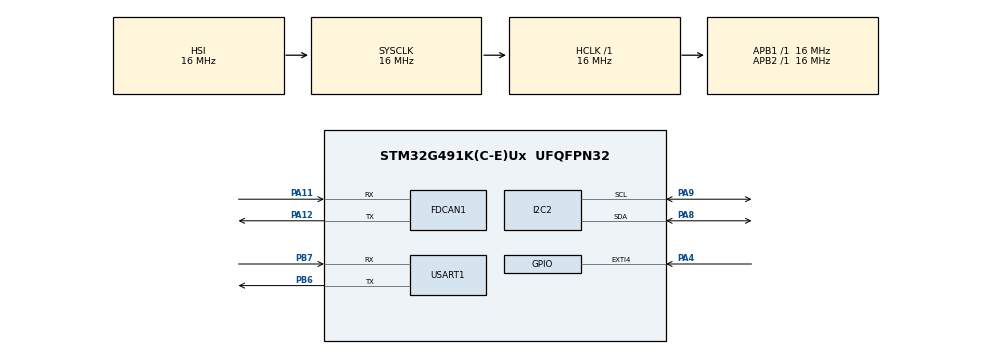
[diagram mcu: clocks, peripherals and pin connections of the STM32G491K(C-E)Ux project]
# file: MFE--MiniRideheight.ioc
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FDCAN1.CalculateBaudRateNominal=333333
FDCAN1.CalculateTimeBitNominal=3000
FDCAN1.CalculateTimeQuantumNominal=1000.0
I2C2.Timing=0x00503D58
Mcu.Family=STM32G4
Mcu.Name=STM32G491K(C-E)Ux
Mcu.Package=UFQFPN32
NVIC.EXTI4_IRQn=true\:0\:0\:false\:false\:true\:true\:true\:true
NVIC.I2C2_EV_IRQn=true\:0\:0\:false\:false\:true\:true\:true\:true
NVIC.PriorityGroup=NVIC_PRIORITYGROUP_4
PA11.Mode=FDCAN_Activate
PA11.Signal=FDCAN1_RX
PA12.Mode=FDCAN_Activate
PA12.Signal=FDCAN1_TX
PA13.Mode=Serial_Wire
PA13.Signal=SYS_JTMS-SWDIO
PA14.Mode=Serial_Wire
PA14.Signal=SYS_JTCK-SWCLK
PA4.GPIO_ModeDefaultEXTI=GPIO_MODE_IT_FALLING
PA4.Signal=GPXTI4
PA8.Mode=I2C
PA8.Signal=I2C2_SDA
PA9.Mode=I2C
PA9.Signal=I2C2_SCL
PB6.Mode=Asynchronous
PB6.Signal=USART1_TX
PB7.Mode=Asynchronous
PB7.Signal=USART1_RX
ProjectManager.HeapSize=0x200
ProjectManager.StackSize=0x400
ProjectManager.TargetToolchain=STM32CubeIDE
RCC.AHBFreq_Value=16000000
RCC.APB1Freq_Value=16000000
RCC.APB1TimFreq_Value=16000000
RCC.APB2Freq_Value=16000000
RCC.APB2TimFreq_Value=16000000
RCC.CortexFreq_Value=16000000
RCC.EXTERNAL_CLOCK_VALUE=12288000
RCC.HCLKFreq_Value=16000000
RCC.HSE_VALUE=8000000
RCC.HSI48_VALUE=48000000
RCC.HSI_VALUE=16000000
RCC.LSE_VALUE=32768
RCC.SYSCLKFreq_VALUE=16000000
RCC.VCOOutputFreq_Value=128000000
USART1.VirtualMode-Asynchronous=VM_ASYNC
VP_SYS_VS_DBSignals.Mode=DisableDeadBatterySignals
board=custom

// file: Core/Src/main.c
/* USER CODE BEGIN Header */
/**
  ******************************************************************************
  * @file           : main.c
  * @brief          : Main program body
  ******************************************************************************
  * @attention
  *
  * Copyright (c) 2026 STMicroelectronics.
  * All rights reserved.
  *
  * This software is licensed under terms that can be found in the LICENSE file
  * in the root directory of this software component.
  * If no LICENSE file comes with this software, it is provided AS-IS.
  *
  ******************************************************************************
  */
/* USER CODE END Header */
#include "main.h"
#include "fdcan.h"
#include "i2c.h"
#include "usart.h"
#include "gpio.h"

/* USER CODE BEGIN Includes */
#include "BoardManager.h"

/* USER CODE END Includes */

/* USER CODE BEGIN PD */
bool data_ready;
void* can_handle;
VL53L4CD_ResultsData_t data;

/* USER CODE END PD */

void SystemClock_Config(void);

int main(void)
{

  /* MCU Configuration--------------------------------------------------------*/

  /* Reset of all peripherals, Initializes the Flash interface and the Systick. */
  HAL_Init();

  /* Configure the system clock */
  SystemClock_Config();

  /* Initialize all configured peripherals */
  MX_GPIO_Init();
  MX_FDCAN1_Init();
  MX_I2C2_Init();
  MX_USART1_UART_Init();
  /* USER CODE BEGIN 2 */
  while (!initializeCAN()){ ; //init fdcan peripheral, keep trying until it works
  	  printf("Fdcan init failed\r\n");
  	  HAL_Delay(20);
  }

  while (!sensor_start()){
	  printf("Sensor not started"); //start the sensor
	  HAL_Delay(20);
  }
  printf("Sensor started\r\n");
  /* USER CODE END 2 */

  /* Infinite loop */
  /* USER CODE BEGIN WHILE */
  while (1)
  {
	  if (data_ready){
		  data_ready = 0;
		  get_data_it();
	  }
    /* USER CODE END WHILE */
  }
}

void SystemClock_Config(void)
{
  RCC_OscInitTypeDef RCC_OscInitStruct = {0};
  RCC_ClkInitTypeDef RCC_ClkInitStruct = {0};

  /** Configure the main internal regulator output voltage
  */
  HAL_PWREx_ControlVoltageScaling(PWR_REGULATOR_VOLTAGE_SCALE1);

  /** Initializes the RCC Oscillators according to the specified parameters
  * in the RCC_OscInitTypeDef structure.
  */
  RCC_OscInitStruct.OscillatorType = RCC_OSCILLATORTYPE_HSI;
  RCC_OscInitStruct.HSIState = RCC_HSI_ON;
  RCC_OscInitStruct.HSICalibrationValue = RCC_HSICALIBRATION_DEFAULT;
  RCC_OscInitStruct.PLL.PLLState = RCC_PLL_NONE;
  if (HAL_RCC_OscConfig(&RCC_OscInitStruct) != HAL_OK)
  {
    Error_Handler();
  }

  /** Initializes the CPU, AHB and APB buses clocks
  */
  RCC_ClkInitStruct.ClockType = RCC_CLOCKTYPE_HCLK|RCC_CLOCKTYPE_SYSCLK
                              |RCC_CLOCKTYPE_PCLK1|RCC_CLOCKTYPE_PCLK2;
  RCC_ClkInitStruct.SYSCLKSource = RCC_SYSCLKSOURCE_HSI;
  RCC_ClkInitStruct.AHBCLKDivider = RCC_SYSCLK_DIV1;
  RCC_ClkInitStruct.APB1CLKDivider = RCC_HCLK_DIV1;
  RCC_ClkInitStruct.APB2CLKDivider = RCC_HCLK_DIV1;

  if (HAL_RCC_ClockConfig(&RCC_ClkInitStruct, FLASH_LATENCY_0) != HAL_OK)
  {
    Error_Handler();
  }
}

void Error_Handler(void)
{
  __disable_irq();
  while (1)
  {
  }
}
